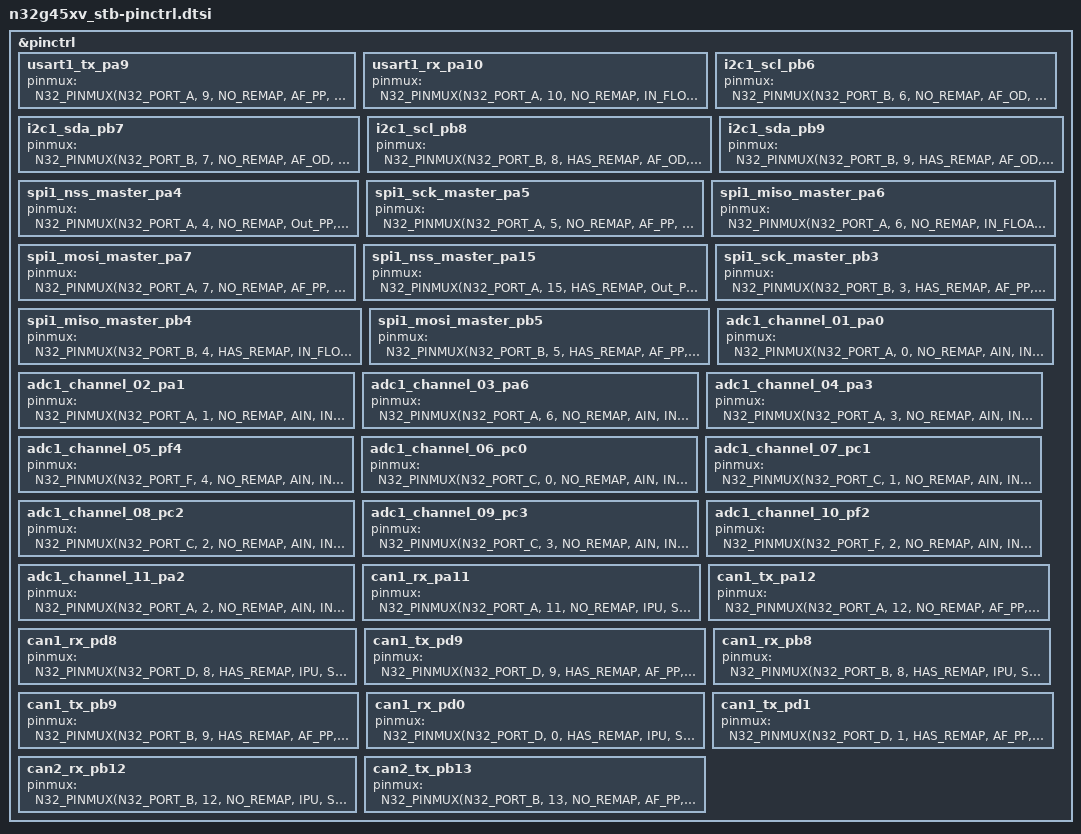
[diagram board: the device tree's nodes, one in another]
/*
 * NOTE: Autogenerated file using genpinctrl.py
 *
 * SPDX-License-Identifier: Apache-2.0
 */
 


#include <nations/n32g45x/n32g45.dtsi>
#include <zephyr/dt-bindings/pinctrl/n32-pinctrl.h>





&pinctrl {

 
    usart1_tx_pa9: usart1_tx_pa9 {
        pinmux=<N32_PINMUX(N32_PORT_A, 9, NO_REMAP, AF_PP, SLEW_RATE_50MHZ)>;
    };
    
    usart1_rx_pa10: usart1_rx_pa10 {
        pinmux=<N32_PINMUX(N32_PORT_A, 10, NO_REMAP, IN_FLOATING, SLEW_RATE_50MHZ)>;
    };

    i2c1_scl_pb6: i2c1_scl_pb6 {
        pinmux=<N32_PINMUX(N32_PORT_B, 6, NO_REMAP, AF_OD, SLEW_RATE_2MHZ)>;
    };
    
    i2c1_sda_pb7: i2c1_sda_pb7 {
        pinmux=<N32_PINMUX(N32_PORT_B, 7, NO_REMAP, AF_OD, SLEW_RATE_2MHZ)>;
    };
    
    i2c1_scl_pb8: i2c1_scl_pb8 {
        pinmux=<N32_PINMUX(N32_PORT_B, 8, HAS_REMAP, AF_OD, SLEW_RATE_2MHZ)>;
    };
    
    i2c1_sda_pb9: i2c1_sda_pb9 {
        pinmux=<N32_PINMUX(N32_PORT_B, 9, HAS_REMAP, AF_OD, SLEW_RATE_2MHZ)>;
    };
			
			
    spi1_nss_master_pa4: spi1_nss_master_pa4 {
        pinmux=<N32_PINMUX(N32_PORT_A, 4, NO_REMAP, Out_PP, SLEW_RATE_50MHZ)>;
    };
    
    spi1_sck_master_pa5: spi1_sck_master_pa5 {
        pinmux=<N32_PINMUX(N32_PORT_A, 5, NO_REMAP, AF_PP, SLEW_RATE_50MHZ)>;
    };

    spi1_miso_master_pa6: spi1_miso_master_pa6 {
        pinmux=<N32_PINMUX(N32_PORT_A, 6, NO_REMAP, IN_FLOATING, SLEW_RATE_50MHZ)>;
    };
    
    spi1_mosi_master_pa7: spi1_mosi_master_pa7 {
        pinmux=<N32_PINMUX(N32_PORT_A, 7, NO_REMAP, AF_PP, SLEW_RATE_50MHZ)>;
    };
    
    
    spi1_nss_master_pa15: spi1_nss_master_pa15 {
        pinmux=<N32_PINMUX(N32_PORT_A, 15, HAS_REMAP, Out_PP, SLEW_RATE_50MHZ)>;
    };
    
    spi1_sck_master_pb3: spi1_sck_master_pb3 {
        pinmux=<N32_PINMUX(N32_PORT_B, 3, HAS_REMAP, AF_PP, SLEW_RATE_50MHZ)>;
    };
    
    spi1_miso_master_pb4: spi1_miso_master_pb4 {
        pinmux=<N32_PINMUX(N32_PORT_B, 4, HAS_REMAP, IN_FLOATING, SLEW_RATE_50MHZ)>;
    };
    
    spi1_mosi_master_pb5: spi1_mosi_master_pb5 {
        pinmux=<N32_PINMUX(N32_PORT_B, 5,  HAS_REMAP, AF_PP, SLEW_RATE_50MHZ)>;
    };
    
    
    adc1_channel_01_pa0: adc1_channel_01_pa0 {
        pinmux=<N32_PINMUX(N32_PORT_A, 0,  NO_REMAP, AIN, INPUT)>;
    };
    
    adc1_channel_02_pa1: adc1_channel_02_pa1 {
        pinmux=<N32_PINMUX(N32_PORT_A, 1,  NO_REMAP, AIN, INPUT)>;
    };
    
    adc1_channel_03_pa6: adc1_channel_03_pa6 {
        pinmux=<N32_PINMUX(N32_PORT_A, 6,  NO_REMAP, AIN, INPUT)>;
    };
    
    adc1_channel_04_pa3: adc1_channel_04_pa3 {
        pinmux=<N32_PINMUX(N32_PORT_A, 3,  NO_REMAP, AIN, INPUT)>;
    };
    
    adc1_channel_05_pf4: adc1_channel_05_pf4 {
        pinmux=<N32_PINMUX(N32_PORT_F, 4,  NO_REMAP, AIN, INPUT)>;
    };
    
    adc1_channel_06_pc0: adc1_channel_06_pc0 {
        pinmux=<N32_PINMUX(N32_PORT_C, 0,  NO_REMAP, AIN, INPUT)>;
    };
    
    adc1_channel_07_pc1: adc1_channel_07_pc1 {
        pinmux=<N32_PINMUX(N32_PORT_C, 1,  NO_REMAP, AIN, INPUT)>;
    };
    
    adc1_channel_08_pc2: adc1_channel_08_pc2 {
        pinmux=<N32_PINMUX(N32_PORT_C, 2,  NO_REMAP, AIN, INPUT)>;
    };
    
    adc1_channel_09_pc3: adc1_channel_09_pc3 {
        pinmux=<N32_PINMUX(N32_PORT_C, 3,  NO_REMAP, AIN, INPUT)>;
    };
    
    adc1_channel_10_pf2: adc1_channel_10_pf2 {
        pinmux=<N32_PINMUX(N32_PORT_F, 2,  NO_REMAP, AIN, INPUT)>;
    };
    
    adc1_channel_11_pa2: adc1_channel_11_pa2 {
        pinmux=<N32_PINMUX(N32_PORT_A, 2,  NO_REMAP, AIN, INPUT)>;
    };







    can1_rx_pa11: can1_rx_pa11 {
        pinmux=<N32_PINMUX(N32_PORT_A, 11,  NO_REMAP, IPU, SLEW_RATE_50MHZ)>;
    };

    can1_tx_pa12: can1_tx_pa12 {
        pinmux=<N32_PINMUX(N32_PORT_A, 12,  NO_REMAP, AF_PP, SLEW_RATE_50MHZ)>;
    };
    
    can1_rx_pd8: can1_rx_pd8 {
        pinmux=<N32_PINMUX(N32_PORT_D, 8,  HAS_REMAP, IPU, SLEW_RATE_50MHZ)>;
    };

    can1_tx_pd9: can1_tx_pd9 {
        pinmux=<N32_PINMUX(N32_PORT_D, 9,  HAS_REMAP, AF_PP, SLEW_RATE_50MHZ)>;
    };
    
    can1_rx_pb8: can1_rx_pb8 {
        pinmux=<N32_PINMUX(N32_PORT_B, 8,  HAS_REMAP, IPU, SLEW_RATE_50MHZ)>;
    };

    can1_tx_pb9: can1_tx_pb9 {
        pinmux=<N32_PINMUX(N32_PORT_B, 9,  HAS_REMAP, AF_PP, SLEW_RATE_50MHZ)>;
    };
    
    can1_rx_pd0: can1_rx_pd0 {
        pinmux=<N32_PINMUX(N32_PORT_D, 0,  HAS_REMAP, IPU, SLEW_RATE_50MHZ)>;
    };

    can1_tx_pd1: can1_tx_pd1 {
        pinmux=<N32_PINMUX(N32_PORT_D, 1,  HAS_REMAP, AF_PP, SLEW_RATE_50MHZ)>;
    };
    
     

    can2_rx_pb12: can2_rx_pb12 {
        pinmux=<N32_PINMUX(N32_PORT_B, 12,  NO_REMAP, IPU, SLEW_RATE_50MHZ)>;
    };

    can2_tx_pb13: can2_tx_pb13 {
        pinmux=<N32_PINMUX(N32_PORT_B, 13,  NO_REMAP, AF_PP, SLEW_RATE_50MHZ)>;
    };
    
};













